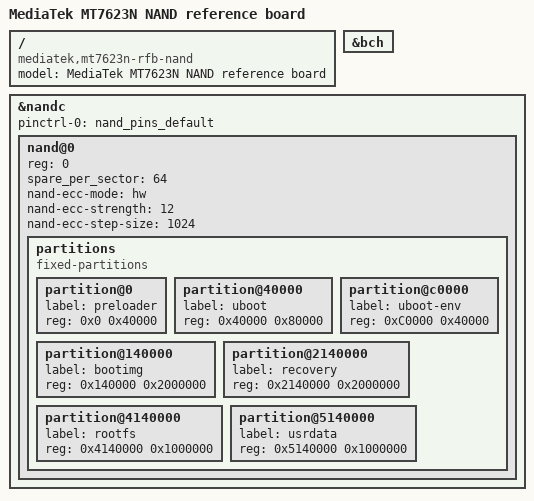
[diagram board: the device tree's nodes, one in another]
// SPDX-License-Identifier: GPL-2.0
/*
 * Copyright (c) 2017 MediaTek Inc.
 * Author: John Crispin <john@phrozen.org>
 *
 */

/dts-v1/;
#include "mt7623n-rfb.dtsi"

/ {
	model = "MediaTek MT7623N NAND reference board";
	compatible = "mediatek,mt7623n-rfb-nand", "mediatek,mt7623";
};

&bch {
	status = "okay";
};

&nandc {
	status = "okay";
	pinctrl-names = "default";
	pinctrl-0 = <&nand_pins_default>;

	nand@0 {
		reg = <0>;
		spare_per_sector = <64>;
		nand-ecc-mode = "hw";
		nand-ecc-strength = <12>;
		nand-ecc-step-size = <1024>;

		partitions {
			compatible = "fixed-partitions";
			#address-cells = <1>;
			#size-cells = <1>;

			partition@0 {
				label = "preloader";
				reg = <0x0 0x40000>;
			};

			partition@40000 {
				label = "uboot";
				reg = <0x40000 0x80000>;
			};

			partition@c0000 {
				label = "uboot-env";
				reg = <0xC0000 0x40000>;
			};

			partition@140000 {
				label = "bootimg";
				reg = <0x140000 0x2000000>;
			};

			partition@2140000 {
				label = "recovery";
				reg = <0x2140000 0x2000000>;
			};

			partition@4140000 {
				label = "rootfs";
				reg = <0x4140000 0x1000000>;
			};

			partition@5140000 {
				label = "usrdata";
				reg = <0x5140000 0x1000000>;
			};
		};
	};
};
